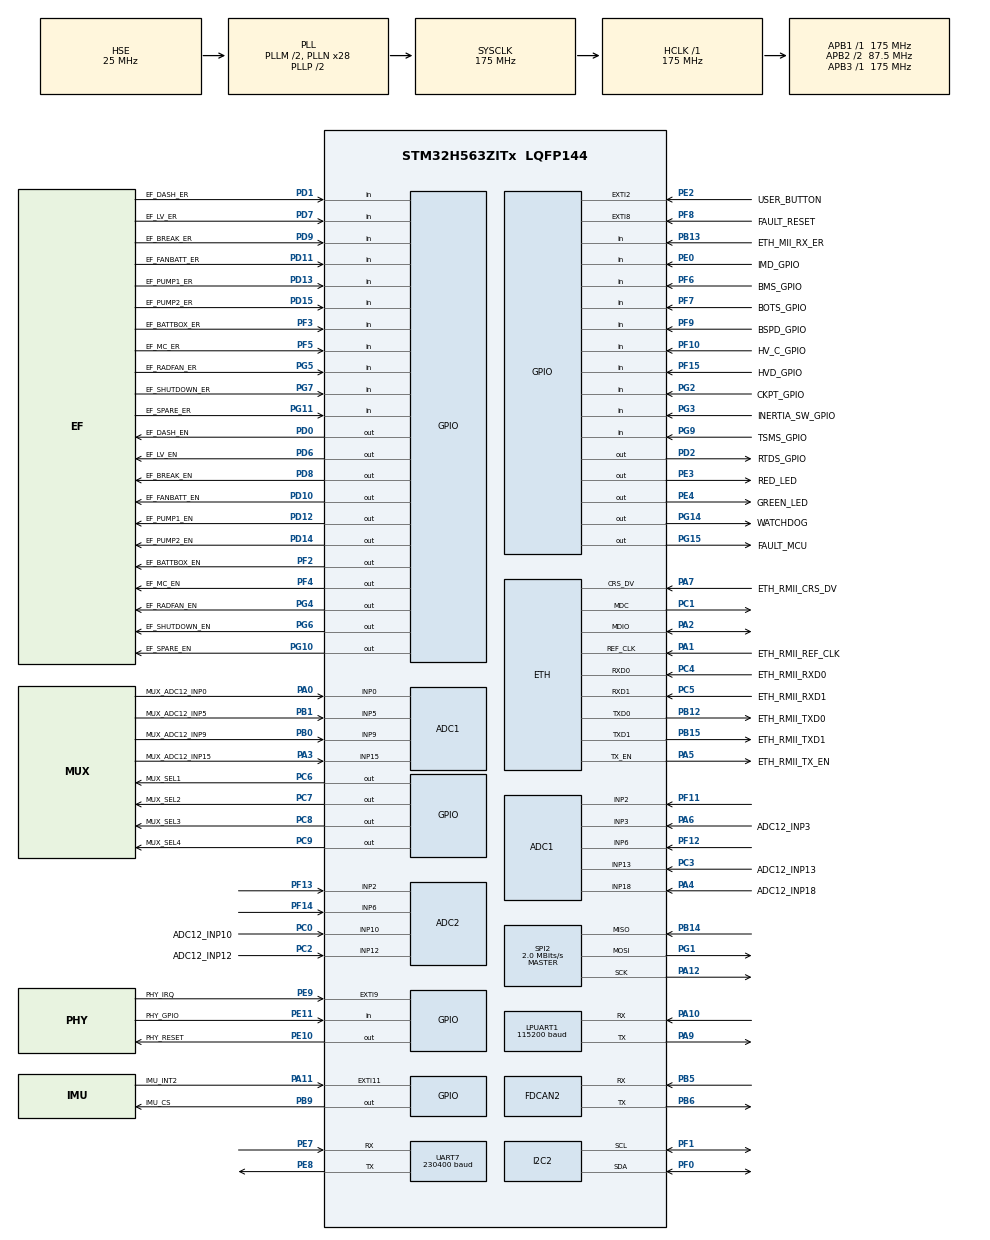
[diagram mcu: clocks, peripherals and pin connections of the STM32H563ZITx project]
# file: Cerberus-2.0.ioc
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ADC1.Channel-11\#ChannelRegularConversion=ADC_CHANNEL_3
ADC1.Channel-22\#ChannelRegularConversion=ADC_CHANNEL_0
ADC1.Channel-23\#ChannelRegularConversion=ADC_CHANNEL_5
ADC1.Channel-24\#ChannelRegularConversion=ADC_CHANNEL_9
ADC1.Channel-25\#ChannelRegularConversion=ADC_CHANNEL_6
ADC1.Channel-26\#ChannelRegularConversion=ADC_CHANNEL_2
ADC1.Channel-27\#ChannelRegularConversion=ADC_CHANNEL_13
ADC1.Channel-28\#ChannelRegularConversion=ADC_CHANNEL_18
ADC1.Channel-29\#ChannelRegularConversion=ADC_CHANNEL_15
ADC1.ClockPrescaler=ADC_CLOCK_ASYNC_DIV64
ADC1.ContinuousConvMode=ENABLE
ADC1.ConversionDataManagement=ADC_CONVERSIONDATA_DMA_CIRCULAR
ADC1.DMAContinuousRequests=ENABLE
ADC1.EOCSelection=ADC_EOC_SEQ_CONV
ADC1.MonitoredBy-11\#ChannelRegularConversion=__NULL
ADC1.MonitoredBy-22\#ChannelRegularConversion=__NULL
ADC1.MonitoredBy-23\#ChannelRegularConversion=__NULL
ADC1.MonitoredBy-24\#ChannelRegularConversion=__NULL
ADC1.MonitoredBy-25\#ChannelRegularConversion=__NULL
ADC1.MonitoredBy-26\#ChannelRegularConversion=__NULL
ADC1.MonitoredBy-27\#ChannelRegularConversion=__NULL
ADC1.MonitoredBy-28\#ChannelRegularConversion=__NULL
ADC1.MonitoredBy-29\#ChannelRegularConversion=__NULL
ADC1.NbrOfConversion=9
ADC1.NbrOfConversionFlag=1
ADC1.OffsetNumber-11\#ChannelRegularConversion=ADC_OFFSET_NONE
ADC1.OffsetNumber-22\#ChannelRegularConversion=ADC_OFFSET_NONE
ADC1.OffsetNumber-23\#ChannelRegularConversion=ADC_OFFSET_NONE
ADC1.OffsetNumber-24\#ChannelRegularConversion=ADC_OFFSET_NONE
ADC1.OffsetNumber-25\#ChannelRegularConversion=ADC_OFFSET_NONE
ADC1.OffsetNumber-26\#ChannelRegularConversion=ADC_OFFSET_NONE
ADC1.OffsetNumber-27\#ChannelRegularConversion=ADC_OFFSET_NONE
ADC1.OffsetNumber-28\#ChannelRegularConversion=ADC_OFFSET_NONE
ADC1.OffsetNumber-29\#ChannelRegularConversion=ADC_OFFSET_NONE
ADC1.Overrun=ADC_OVR_DATA_OVERWRITTEN
ADC1.Rank-11\#ChannelRegularConversion=1
ADC1.Rank-22\#ChannelRegularConversion=2
ADC1.Rank-23\#ChannelRegularConversion=3
ADC1.Rank-24\#ChannelRegularConversion=4
ADC1.Rank-25\#ChannelRegularConversion=5
ADC1.Rank-26\#ChannelRegularConversion=6
ADC1.Rank-27\#ChannelRegularConversion=7
ADC1.Rank-28\#ChannelRegularConversion=8
ADC1.Rank-29\#ChannelRegularConversion=9
ADC1.SamplingTime-11\#ChannelRegularConversion=ADC_SAMPLETIME_47CYCLES_5
ADC1.SamplingTime-22\#ChannelRegularConversion=ADC_SAMPLETIME_47CYCLES_5
ADC1.SamplingTime-23\#ChannelRegularConversion=ADC_SAMPLETIME_47CYCLES_5
ADC1.SamplingTime-24\#ChannelRegularConversion=ADC_SAMPLETIME_47CYCLES_5
ADC1.SamplingTime-25\#ChannelRegularConversion=ADC_SAMPLETIME_47CYCLES_5
ADC1.SamplingTime-26\#ChannelRegularConversion=ADC_SAMPLETIME_47CYCLES_5
ADC1.SamplingTime-27\#ChannelRegularConversion=ADC_SAMPLETIME_47CYCLES_5
ADC1.SamplingTime-28\#ChannelRegularConversion=ADC_SAMPLETIME_47CYCLES_5
ADC1.SamplingTime-29\#ChannelRegularConversion=ADC_SAMPLETIME_247CYCLES_5
ADC1.master=1
ADC2.Channel-2\#ChannelRegularConversion=ADC_CHANNEL_12
ADC2.Channel-3\#ChannelRegularConversion=ADC_CHANNEL_10
ADC2.Channel-4\#ChannelRegularConversion=ADC_CHANNEL_2
ADC2.Channel-5\#ChannelRegularConversion=ADC_CHANNEL_6
ADC2.ClockPrescaler=ADC_CLOCK_ASYNC_DIV64
ADC2.ContinuousConvMode=ENABLE
ADC2.ConversionDataManagement=ADC_CONVERSIONDATA_DMA_CIRCULAR
ADC2.DMAContinuousRequests=ENABLE
ADC2.EOCSelection=ADC_EOC_SEQ_CONV
ADC2.MonitoredBy-2\#ChannelRegularConversion=__NULL
ADC2.MonitoredBy-3\#ChannelRegularConversion=__NULL
ADC2.MonitoredBy-4\#ChannelRegularConversion=__NULL
ADC2.MonitoredBy-5\#ChannelRegularConversion=__NULL
ADC2.NbrOfConversion=4
ADC2.NbrOfConversionFlag=1
ADC2.OffsetNumber-2\#ChannelRegularConversion=ADC_OFFSET_NONE
ADC2.OffsetNumber-3\#ChannelRegularConversion=ADC_OFFSET_NONE
ADC2.OffsetNumber-4\#ChannelRegularConversion=ADC_OFFSET_NONE
ADC2.OffsetNumber-5\#ChannelRegularConversion=ADC_OFFSET_NONE
ADC2.Overrun=ADC_OVR_DATA_OVERWRITTEN
ADC2.Rank-2\#ChannelRegularConversion=1
ADC2.Rank-3\#ChannelRegularConversion=2
ADC2.Rank-4\#ChannelRegularConversion=3
ADC2.Rank-5\#ChannelRegularConversion=4
ADC2.SamplingTime-2\#ChannelRegularConversion=ADC_SAMPLETIME_2CYCLES_5
ADC2.SamplingTime-3\#ChannelRegularConversion=ADC_SAMPLETIME_2CYCLES_5
ADC2.SamplingTime-4\#ChannelRegularConversion=ADC_SAMPLETIME_2CYCLES_5
ADC2.SamplingTime-5\#ChannelRegularConversion=ADC_SAMPLETIME_2CYCLES_5
BOOTPATH.BootPathName=LEGACY
BOOTPATH.UserSelectedBootPath=LEGACY
CORTEX_M33_NS.userName=CORTEX_M33
ETH.MediaInterface=HAL_ETH_RMII_MODE
FDCAN2.CalculateBaudRateNominal=500000
FDCAN2.CalculateTimeBitNominal=2000
FDCAN2.CalculateTimeQuantumNominal=125.0
FDCAN2.ExtFiltersNbr=8
FDCAN2.Mode=FDCAN_MODE_NORMAL
FDCAN2.NominalPrescaler=8
FDCAN2.NominalTimeSeg1=11
FDCAN2.NominalTimeSeg2=4
FDCAN2.StdFiltersNbr=12
GPDMA1.CIRCULARMODE_GPDMACH4=ENABLE
GPDMA1.CIRCULARMODE_GPDMACH5=ENABLE
GPDMA1.DESTDATAWIDTH_GPDMACH4=DMA_DEST_DATAWIDTH_HALFWORD
GPDMA1.DESTDATAWIDTH_GPDMACH5=DMA_DEST_DATAWIDTH_HALFWORD
GPDMA1.DESTINC_GPDMACH4=DMA_DINC_INCREMENTED
GPDMA1.DESTINC_GPDMACH5=DMA_DINC_INCREMENTED
GPDMA1.DIRECTION_GPDMACH0=DMA_MEMORY_TO_PERIPH
GPDMA1.IPHANDLE_GPDMACH0-SIMPLEREQUEST_GPDMACH0=__NULL
GPDMA1.IPHANDLE_GPDMACH4-SIMPLEREQUEST_GPDMACH4=__NULL
GPDMA1.IPHANDLE_GPDMACH5-SIMPLEREQUEST_GPDMACH5=__NULL
GPDMA1.PRIORITY_GPDMACH0=DMA_LOW_PRIORITY_MID_WEIGHT
GPDMA1.REQUEST_GPDMACH0=GPDMA1_REQUEST_UART7_TX
GPDMA1.REQUEST_GPDMACH4=GPDMA1_REQUEST_ADC2
GPDMA1.REQUEST_GPDMACH5=GPDMA1_REQUEST_ADC1
GPDMA1.SRCDATAWIDTH_GPDMACH4=DMA_SRC_DATAWIDTH_HALFWORD
GPDMA1.SRCDATAWIDTH_GPDMACH5=DMA_SRC_DATAWIDTH_HALFWORD
GPDMA1.SRCINC_GPDMACH0=DMA_SINC_INCREMENTED
I2C2.Timing=0x60606293
IWDG.Prescaler=IWDG_PRESCALER_32
LPUART1.BaudRate=115200
Mcu.Family=STM32H5
Mcu.Name=STM32H563ZITx
Mcu.Package=LQFP144
NETXDUO.ETH_ON=1
NETXDUO.NX_APP_MEM_POOL_SIZE=10240
NETXDUO.NX_ENABLE_VLAN=false
NETXDUO.NX_MAX_MULTICAST_GROUPS=256
NVIC.ETH_IRQn=true\:0\:0\:false\:false\:true\:false\:true\:true\:true
NVIC.ETH_WKUP_IRQn=true\:0\:0\:false\:false\:true\:false\:true\:true\:true
NVIC.EXTI11_IRQn=true\:0\:0\:false\:false\:true\:false\:true\:true\:true
NVIC.EXTI2_IRQn=true\:0\:0\:false\:false\:true\:false\:true\:true\:true
NVIC.EXTI8_IRQn=true\:0\:0\:false\:false\:true\:false\:true\:true\:true
NVIC.FDCAN2_IT0_IRQn=true\:0\:0\:false\:false\:true\:false\:true\:true\:true
NVIC.FDCAN2_IT1_IRQn=true\:0\:0\:false\:false\:true\:false\:true\:true\:true
NVIC.GPDMA1_Channel0_IRQn=true\:0\:0\:false\:false\:true\:true\:false\:true\:true
NVIC.GPDMA1_Channel4_IRQn=true\:0\:0\:false\:false\:true\:true\:false\:true\:true
NVIC.GPDMA1_Channel5_IRQn=true\:0\:0\:false\:false\:true\:true\:false\:true\:true
NVIC.PriorityGroup=NVIC_PRIORITYGROUP_4
NVIC.TIM1_UP_IRQn=true\:15\:0\:false\:false\:true\:false\:false\:true\:true
NVIC.TimeBase=TIM1_UP_IRQn
NVIC.TimeBaseIP=TIM1
NVIC.UART7_IRQn=true\:0\:0\:false\:false\:true\:false\:true\:true\:true
PA0.GPIO_Label=MUX_ADC12_INP0
PA0.Signal=ADCx_INP0
PA1.GPIO_Label=ETH_RMII_REF_CLK
PA1.Mode=RMII
PA1.Signal=ETH_REF_CLK
PA10.Mode=Asynchronous
PA10.Signal=LPUART1_RX
PA11.GPIO_Label=IMU_INT2
PA11.Signal=GPXTI11
PA12.Mode=Full_Duplex_Master
PA12.Signal=SPI2_SCK
PA13(JTMS/SWDIO).GPIO_Label=JTMS
PA13(JTMS/SWDIO).Signal=DEBUG_JTMS-SWDIO
PA14(JTCK/SWCLK).GPIO_Label=JTCK
PA14(JTCK/SWCLK).Signal=DEBUG_JTCK-SWCLK
PA15(JTDI).GPIO_Label=JTDI
PA15(JTDI).Signal=DEBUG_JTDI
PA2.Mode=RMII
PA2.Signal=ETH_MDIO
PA3.GPIO_Label=MUX_ADC12_INP15
PA3.Signal=ADCx_INP15
PA4.GPIO_Label=ADC12_INP18
PA4.Signal=ADCx_INP18
PA5.GPIO_Label=ETH_RMII_TX_EN
PA5.Mode=RMII
PA5.Signal=ETH_TX_EN
PA6.GPIO_Label=ADC12_INP3
PA6.Signal=ADCx_INP3
PA7.GPIO_Label=ETH_RMII_CRS_DV
PA7.Mode=RMII
PA7.Signal=ETH_CRS_DV
PA9.Mode=Asynchronous
PA9.Signal=LPUART1_TX
PB0.GPIO_Label=MUX_ADC12_INP9
PB0.Signal=ADCx_INP9
PB1.GPIO_Label=MUX_ADC12_INP5
PB1.Signal=ADCx_INP5
PB12.GPIO_Label=ETH_RMII_TXD0
PB12.Mode=RMII
PB12.Signal=ETH_TXD0
PB13.GPIO_Label=ETH_MII_RX_ER
PB13.Signal=GPIO_Input
PB14.Mode=Full_Duplex_Master
PB14.Signal=SPI2_MISO
PB15.GPIO_Label=ETH_RMII_TXD1
PB15.Mode=RMII
PB15.Signal=ETH_TXD1
PB3(JTDO/TRACESWO).GPIO_Label=JTDO
PB3(JTDO/TRACESWO).Signal=DEBUG_JTDO-SWO
PB5.Mode=FDCAN_Activate
PB5.Signal=FDCAN2_RX
PB6.Mode=FDCAN_Activate
PB6.Signal=FDCAN2_TX
PB9.GPIO_Label=IMU_CS
PB9.PinState=GPIO_PIN_SET
PB9.Signal=GPIO_Output
PC0.GPIO_Label=ADC12_INP10
PC0.Signal=ADCx_INP10
PC1.Mode=RMII
PC1.Signal=ETH_MDC
PC14-OSC32_IN(OSC32_IN).Mode=LSE-External-Oscillator
PC14-OSC32_IN(OSC32_IN).Signal=RCC_OSC32_IN
PC15-OSC32_OUT(OSC32_OUT).Mode=LSE-External-Oscillator
PC15-OSC32_OUT(OSC32_OUT).Signal=RCC_OSC32_OUT
PC2.GPIO_Label=ADC12_INP12
PC2.Signal=ADCx_INP12
PC3.GPIO_Label=ADC12_INP13
PC3.Signal=ADCx_INP13
PC4.GPIO_Label=ETH_RMII_RXD0
PC4.Mode=RMII
PC4.Signal=ETH_RXD0
PC5.GPIO_Label=ETH_RMII_RXD1
PC5.Mode=RMII
PC5.Signal=ETH_RXD1
PC6.GPIO_Label=MUX_SEL1
PC6.Signal=GPIO_Output
PC7.GPIO_Label=MUX_SEL2
PC7.Signal=GPIO_Output
PC8.GPIO_Label=MUX_SEL3
PC8.Signal=GPIO_Output
PC9.GPIO_Label=MUX_SEL4
PC9.Signal=GPIO_Output
PD0.GPIO_Label=EF_DASH_EN
PD0.Signal=GPIO_Output
PD1.GPIO_Label=EF_DASH_ER
PD1.GPIO_PuPd=GPIO_PULLUP
PD1.Signal=GPIO_Input
PD10.GPIO_Label=EF_FANBATT_EN
PD10.Signal=GPIO_Output
PD11.GPIO_Label=EF_FANBATT_ER
PD11.GPIO_PuPd=GPIO_PULLUP
PD11.Signal=GPIO_Input
PD12.GPIO_Label=EF_PUMP1_EN
PD12.Signal=GPIO_Output
PD13.GPIO_Label=EF_PUMP1_ER
PD13.GPIO_PuPd=GPIO_PULLUP
PD13.Signal=GPIO_Input
PD14.GPIO_Label=EF_PUMP2_EN
PD14.Signal=GPIO_Output
PD15.GPIO_Label=EF_PUMP2_ER
PD15.GPIO_PuPd=GPIO_PULLUP
PD15.Signal=GPIO_Input
PD2.GPIO_Label=RTDS_GPIO
PD2.Signal=GPIO_Output
PD6.GPIO_Label=EF_LV_EN
PD6.GPIO_PuPd=GPIO_PULLUP
PD6.PinState=GPIO_PIN_SET
PD6.Signal=GPIO_Output
PD7.GPIO_Label=EF_LV_ER
PD7.GPIO_PuPd=GPIO_PULLUP
PD7.Signal=GPIO_Input
PD8.GPIO_Label=EF_BREAK_EN
PD8.Signal=GPIO_Output
PD9.GPIO_Label=EF_BREAK_ER
PD9.GPIO_PuPd=GPIO_PULLUP
PD9.Signal=GPIO_Input
PE0.GPIO_Label=IMD_GPIO
PE0.Signal=GPIO_Input
PE10.GPIO_Label=PHY_RESET
PE10.Signal=GPIO_Output
PE11.GPIO_Label=PHY_GPIO
PE11.Signal=GPIO_Input
PE2.GPIO_Label=USER_BUTTON
PE2.GPIO_ModeDefaultEXTI=GPIO_MODE_IT_FALLING
PE2.GPIO_PuPd=GPIO_PULLUP
PE2.Signal=GPXTI2
PE3.GPIO_Label=RED_LED
PE3.Signal=GPIO_Output
PE4.GPIO_Label=GREEN_LED
PE4.Signal=GPIO_Output
PE7.Mode=Asynchronous
PE7.Signal=UART7_RX
PE8.Mode=Asynchronous
PE8.Signal=UART7_TX
PE9.GPIO_Label=PHY_IRQ
PE9.GPIO_ModeDefaultEXTI=GPIO_MODE_IT_FALLING
PE9.Signal=GPXTI9
PF0.Mode=I2C
PF0.Signal=I2C2_SDA
PF1.Mode=I2C
PF1.Signal=I2C2_SCL
PF10.GPIO_Label=HV_C_GPIO
PF10.Signal=GPIO_Input
PF11.Mode=IN2-Single-Ended
PF11.Signal=ADC1_INP2
PF12.Mode=IN6-Single-Ended
PF12.Signal=ADC1_INP6
PF13.Mode=IN2-Single-Ended
PF13.Signal=ADC2_INP2
PF14.Mode=IN6-Single-Ended
PF14.Signal=ADC2_INP6
PF15.GPIO_Label=HVD_GPIO
PF15.Signal=GPIO_Input
PF2.GPIO_Label=EF_BATTBOX_EN
PF2.GPIO_PuPd=GPIO_PULLUP
PF2.PinState=GPIO_PIN_SET
PF2.Signal=GPIO_Output
PF3.GPIO_Label=EF_BATTBOX_ER
PF3.GPIO_PuPd=GPIO_PULLUP
PF3.Signal=GPIO_Input
PF4.GPIO_Label=EF_MC_EN
PF4.Signal=GPIO_Output
PF5.GPIO_Label=EF_MC_ER
PF5.GPIO_PuPd=GPIO_PULLUP
PF5.Signal=GPIO_Input
PF6.GPIO_Label=BMS_GPIO
PF6.Signal=GPIO_Input
PF7.GPIO_Label=BOTS_GPIO
PF7.Signal=GPIO_Input
PF8.GPIO_Label=FAULT_RESET
PF8.GPIO_ModeDefaultEXTI=GPIO_MODE_IT_FALLING
PF8.Signal=GPXTI8
PF9.GPIO_Label=BSPD_GPIO
PF9.Signal=GPIO_Input
PG1.Mode=Full_Duplex_Master
PG1.Signal=SPI2_MOSI
PG10.GPIO_Label=EF_SPARE_EN
PG10.Signal=GPIO_Output
PG11.GPIO_Label=EF_SPARE_ER
PG11.GPIO_PuPd=GPIO_PULLUP
PG11.Signal=GPIO_Input
PG14.GPIO_Label=WATCHDOG
PG14.Signal=GPIO_Output
PG15.GPIO_Label=FAULT_MCU
PG15.PinState=GPIO_PIN_SET
PG15.Signal=GPIO_Output
PG2.GPIO_Label=CKPT_GPIO
PG2.Signal=GPIO_Input
PG3.GPIO_Label=INERTIA_SW_GPIO
PG3.Signal=GPIO_Input
PG4.GPIO_Label=EF_RADFAN_EN
PG4.Signal=GPIO_Output
PG5.GPIO_Label=EF_RADFAN_ER
PG5.GPIO_PuPd=GPIO_PULLUP
PG5.Signal=GPIO_Input
PG6.GPIO_Label=EF_SHUTDOWN_EN
PG6.GPIO_PuPd=GPIO_PULLUP
PG6.PinState=GPIO_PIN_SET
PG6.Signal=GPIO_Output
PG7.GPIO_Label=EF_SHUTDOWN_ER
PG7.GPIO_PuPd=GPIO_PULLUP
PG7.Signal=GPIO_Input
PG9.GPIO_Label=TSMS_GPIO
PG9.Signal=GPIO_Input
PH0-OSC_IN(PH0).Mode=HSE-External-Oscillator
PH0-OSC_IN(PH0).Signal=RCC_OSC_IN
PH1-OSC_OUT(PH1).Mode=HSE-External-Oscillator
PH1-OSC_OUT(PH1).Signal=RCC_OSC_OUT
ProjectManager.HeapSize=0x200
ProjectManager.StackSize=0x400
ProjectManager.TargetToolchain=CMake
RCC.ADCFreq_Value=175000000
RCC.AHBFreq_Value=175000000
RCC.APB1Freq_Value=175000000
RCC.APB1TimFreq_Value=175000000
RCC.APB2CLKDivider=RCC_HCLK_DIV2
RCC.APB2Freq_Value=87500000
RCC.APB2TimFreq_Value=175000000
RCC.APB3Freq_Value=175000000
RCC.CSI_VALUE=4000000
RCC.CortexFreq_Value=175000000
RCC.EPOD_VALUE=25000000
RCC.FDCANClockSelection=RCC_FDCANCLKSOURCE_PLL2Q
RCC.HCLKFreq_Value=175000000
RCC.HSE_VALUE=25000000
RCC.HSI48_VALUE=48000000
RCC.HSI_VALUE=64000000
RCC.LSIRC_VALUE=32000
RCC.PLL1Q=7
RCC.PLL2FRACN=0
RCC.PLL2M=5
RCC.PLL2N=64
RCC.PLL2P=5
RCC.PLL2Q=5
RCC.PLL2Source=RCC_PLL2_SOURCE_HSE
RCC.PLLFRACN=0
RCC.PLLM=2
RCC.PLLN=28
RCC.PLLSourceVirtual=RCC_PLL1_SOURCE_HSE
RCC.SPI2CLockSelection=RCC_SPI2CLKSOURCE_PLL2P
RCC.SYSCLKFreq_VALUE=175000000
RCC.SYSCLKSource=RCC_SYSCLKSOURCE_PLLCLK
RCC.USBFreq_Value=48000000
RCC.VCOOutputFreq_Value=350000000
SH.ADCx_INP0.0=ADC1_INP0,IN0-Single-Ended
SH.ADCx_INP0.1=ADC2_INP0,IN0-Single-Ended
SH.ADCx_INP10.0=ADC1_INP10
SH.ADCx_INP10.1=ADC2_INP10,IN10-Single-Ended
SH.ADCx_INP12.0=ADC1_INP12
SH.ADCx_INP12.1=ADC2_INP12,IN12-Single-Ended
SH.ADCx_INP13.0=ADC1_INP13,IN13-Single-Ended
SH.ADCx_INP13.1=ADC2_INP13,IN13-Single-Ended
SH.ADCx_INP15.0=ADC1_INP15,IN15-Single-Ended
SH.ADCx_INP15.1=ADC2_INP15,IN15-Single-Ended
SH.ADCx_INP18.0=ADC2_INP18
SH.ADCx_INP18.1=ADC1_INP18,IN18-Single-Ended
SH.ADCx_INP3.0=ADC2_INP3
SH.ADCx_INP3.1=ADC1_INP3,IN3-Single-Ended
SH.ADCx_INP5.0=ADC2_INP5
SH.ADCx_INP5.1=ADC1_INP5,IN5-Single-Ended
SH.ADCx_INP9.0=ADC1_INP9,IN9-Single-Ended
SH.ADCx_INP9.1=ADC2_INP9,IN9-Single-Ended
SPI2.BaudRatePrescaler=SPI_BAUDRATEPRESCALER_32
SPI2.CalculateBaudRate=2.0 MBits/s
SPI2.DataSize=SPI_DATASIZE_8BIT
SPI2.Direction=SPI_DIRECTION_2LINES
SPI2.Mode=SPI_MODE_MASTER
SPI2.VirtualType=VM_MASTER
THREADX.TX_APP_GENERATE_INIT_CODE=false
THREADX.TX_APP_MEM_POOL_SIZE=46080
THREADX.TX_ENABLE_EVENT_TRACE=1
THREADX.TX_TIMER_TICKS_PER_SECOND=1000
UART7.BaudRate=230400
UART7.Mode=MODE_TX
VP_BOOTPATH_VS_BOOTPATH.Mode=BP_Activate
VP_CORTEX_M33_NS_VS_Hclk.Mode=Hclk_Mode
VP_DCACHE1_VS_DCACHE.Mode=DCACHE_Activate
VP_GPDMA1_VS_GPDMACH0.Mode=SIMPLEREQUEST_GPDMACH0
VP_GPDMA1_VS_GPDMACH4.Mode=SIMPLEREQUEST_GPDMACH4
VP_GPDMA1_VS_GPDMACH5.Mode=SIMPLEREQUEST_GPDMACH5
VP_ICACHE_VS_ICACHE.Mode=DirectMappedCache
VP_IWDG_VS_IWDG.Mode=IWDG_Activate
VP_MEMORYMAP_VS_MEMORYMAP.Mode=CurAppReg
VP_NETXDUO_VS_AddonsOoMQTT.Mode=Addons_MQTT
VP_NETXDUO_VS_EthernetOoPhyOoInterface.Mode=Custom_Phy_Interface
VP_NETXDUO_VS_NXOoCore.Mode=NX_Core
VP_NETXDUO_VS_NetworkOoInterface.Mode=Ethernet_Interface
VP_PWR_VS_LPOM.Mode=PowerOptimisation
VP_PWR_VS_SECSignals.Mode=Security/Privilege
VP_SYS_VS_tim1.Mode=TIM1
VP_THREADX_VS_RTOSJjThreadXJjCoreJjDefault.Mode=Core_Default
VP_THREADX_VS_RTOSJjThreadXJjTraceX_SupportJjDefault.Mode=TraceX_Support_Default
board=custom

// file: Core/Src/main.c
/* USER CODE BEGIN Header */
/**
  ******************************************************************************
  * @file           : main.c
  * @brief          : Main program body
  ******************************************************************************
  * @attention
  *
  * Copyright (c) 2025 STMicroelectronics.
  * All rights reserved.
  *
  * This software is licensed under terms that can be found in the LICENSE file
  * in the root directory of this software component.
  * If no LICENSE file comes with this software, it is provided AS-IS.
  *
  ******************************************************************************
  */
/* USER CODE END Header */
#include "app_threadx.h"
#include "main.h"

/* USER CODE BEGIN Includes */
#include <stdio.h>
#include <string.h>
#include <stdint.h>

#include "fdcan.h"
#include "u_can.h"
#include "u_faults.h"
#include "u_queues.h"
#include "u_debug.h"
#include "u_lightning.h"
#include "u_tx_debug.h"
#include "traceout.h"
#include "can_messages_tx.h"
/* USER CODE END Includes */

ETH_DMADescTypeDef  DMARxDscrTab[ETH_RX_DESC_CNT]; /* Ethernet Rx DMA Descriptors */
ETH_DMADescTypeDef  DMATxDscrTab[ETH_TX_DESC_CNT]; /* Ethernet Tx DMA Descriptors */

ADC_HandleTypeDef hadc1;
ADC_HandleTypeDef hadc2;
DMA_NodeTypeDef Node_GPDMA1_Channel5;
DMA_QListTypeDef List_GPDMA1_Channel5;
DMA_HandleTypeDef handle_GPDMA1_Channel5;
DMA_NodeTypeDef Node_GPDMA1_Channel4;
DMA_QListTypeDef List_GPDMA1_Channel4;
DMA_HandleTypeDef handle_GPDMA1_Channel4;

DCACHE_HandleTypeDef hdcache1;

ETH_HandleTypeDef heth;

FDCAN_HandleTypeDef hfdcan2;

I2C_HandleTypeDef hi2c2;

IWDG_HandleTypeDef hiwdg;

UART_HandleTypeDef hlpuart1;
UART_HandleTypeDef huart7;
DMA_HandleTypeDef handle_GPDMA1_Channel0;

SPI_HandleTypeDef hspi2;

void SystemClock_Config(void);
void PeriphCommonClock_Config(void);
static void MX_GPDMA1_Init(void);
static void MX_GPIO_Init(void);
static void MX_ICACHE_Init(void);
static void MX_ADC1_Init(void);
static void MX_ADC2_Init(void);
static void MX_FDCAN2_Init(void);
static void MX_ETH_Init(void);
static void MX_I2C2_Init(void);
static void MX_LPUART1_UART_Init(void);
static void MX_SPI2_Init(void);
static void MX_UART7_Init(void);
static void MX_DCACHE1_Init(void);
static void MX_IWDG_Init(void);

/* USER CODE BEGIN 0 */

/* Make printf() use LPUART1 */
int _write(int file, char *ptr, int len)
{
    HAL_UART_Transmit(&hlpuart1, (uint8_t*)ptr, len, HAL_MAX_DELAY);
    return len;
}

/* FDCAN FIFO0 Interrupt Callback */
/* Callback for any FIFO0 interrupt stuff */
void HAL_FDCAN_RxFifo0Callback(FDCAN_HandleTypeDef *hfdcan, uint32_t RxFifo0ITs)
{
  //PRINTLN_INFO("HAL_FDCAN callback triggered");

	/* If a message has just been recieved... */
	if (RxFifo0ITs & FDCAN_IT_RX_FIFO0_NEW_MESSAGE)
	{
		can_msg_t message;
		FDCAN_RxHeaderTypeDef rx_header;

    /* Get the message. */
    HAL_StatusTypeDef status = HAL_FDCAN_GetRxMessage(hfdcan, FDCAN_RX_FIFO0, &rx_header, message.data);
    if(status != HAL_OK) {
      PRINTLN_ERROR("Failed to call HAL_FDCAN_GetRxMessage() (Status: %d/%s).", status, hal_status_toString(status));
      queue_send(&faults, &(fault_t){CAN_INCOMING_FAULT}, TX_NO_WAIT);
      return;
    }

    /* Pack the message into the struct. */
    message.id = rx_header.Identifier;
		message.id_is_extended = (rx_header.IdType == FDCAN_EXTENDED_ID);
	  message.len = (uint8_t)rx_header.DataLength;

		/* Check message size */
		if (rx_header.DataLength > 8)
		{
			PRINTLN_ERROR("Recieved CAN message is larger than 8 bytes (rx_header.DataLength: %ld, id: 0x%lX).", rx_header.DataLength, rx_header.Identifier);
      queue_send(&faults, &(fault_t){CAN_INCOMING_FAULT}, TX_NO_WAIT);
			return;
		}

		/* Send message to incoming CAN queue */
    queue_send(&can_incoming, &message, TX_NO_WAIT);
	}
}

/* BusOff Error Handling. */
void HAL_FDCAN_ErrorStatusCallback(FDCAN_HandleTypeDef *hfdcan, uint32_t ErrorStatusITs)
{
    FDCAN_ProtocolStatusTypeDef protocol_status;
    HAL_FDCAN_GetProtocolStatus(hfdcan, &protocol_status);

    if (protocol_status.BusOff != 0)  // If Bus-Off error occurred
    {
        PRINTLN_ERROR("CAN ENCOUNTERED BUS OFF STATE");
        CLEAR_BIT(hfdcan->Instance->CCCR, FDCAN_CCCR_INIT);  // Clear INIT bit to recover from Bus-Off
        /* get the FDCAN hal errors. */
        uint8_t status = HAL_FDCAN_GetError(can1.hcan);
        printf("can - HAL_FDCAN_GetError() status: %d\n", status);

        FDCAN_ProtocolStatusTypeDef statt = { 0 };
        status = HAL_FDCAN_GetProtocolStatus(can1.hcan, &statt);
        printf("can - HAL_FDCAN_GetProtocolStatus() status: %d\n", status);

        /* Big statt */
        printf("can - HAL_FDCAN_GetProtocolStatus() - LastErrorCode=%ld\n", statt.LastErrorCode);
        printf("can - HAL_FDCAN_GetProtocolStatus() - DataLastErrorCode=%ld\n", statt.DataLastErrorCode);
        printf("can - HAL_FDCAN_GetProtocolStatus() - Activity=%ld\n", statt.Activity);
        printf("can - HAL_FDCAN_GetProtocolStatus() - ErrorPassive=%ld\n", statt.ErrorPassive);
        printf("can - HAL_FDCAN_GetProtocolStatus() - Warning=%ld\n", statt.Warning);
        printf("can - HAL_FDCAN_GetProtocolStatus() - BusOff=%ld\n", statt.BusOff);
        printf("can - HAL_FDCAN_GetProtocolStatus() - RxESIflag=%ld\n", statt.RxESIflag);
        printf("can - HAL_FDCAN_GetProtocolStatus() - RxBRSflag=%ld\n", statt.RxBRSflag);
        printf("can - HAL_FDCAN_GetProtocolStatus() - RxFDFflag=%ld\n", statt.RxFDFflag);
        printf("can - HAL_FDCAN_GetProtocolStatus() - ProtocolException=%ld\n", statt.ProtocolException);
        printf("can - HAL_FDCAN_GetProtocolStatus() - TDCvalue=%ld\n", statt.TDCvalue);

        FDCAN_ErrorCountersTypeDef statt2 = { 0 };
        status = HAL_FDCAN_GetErrorCounters(can1.hcan, &statt2);
        printf("can - HAL_FDCAN_GetErrorCounters() status: %d\n", status);
        printf("can - HAL_FDCAN_GetErrorCounters() - TxErrorCnt: %ld\n", statt2.TxErrorCnt);
        printf("can - HAL_FDCAN_GetErrorCounters() - RxErrorCnt: %ld\n", statt2.RxErrorCnt);
        printf("can - HAL_FDCAN_GetErrorCounters() - RxErrorPassive: %ld\n", statt2.RxErrorPassive);
        printf("can - HAL_FDCAN_GetErrorCounters() - ErrorLogging: %ld\n", statt2.ErrorLogging);
    }
}

void HAL_GPIO_EXTI_Falling_Callback(uint16_t GPIO_Pin)
{
	if (GPIO_Pin == USER_BUTTON_Pin) {
		traceout_start_from_isr();
	}

  if (GPIO_Pin == FAULT_RESET_Pin) {
    send_reset_latching_fault(true);
  }
}

/* USER CODE END 0 */

int main(void)
{

  /* MCU Configuration--------------------------------------------------------*/

  /* Reset of all peripherals, Initializes the Flash interface and the Systick. */
  HAL_Init();

  /* Configure the system clock */
  SystemClock_Config();

  /* Configure the peripherals common clocks */
  PeriphCommonClock_Config();

  /* USER CODE BEGIN SysInit */
  //HAL_Delay(10000);
  /* USER CODE END SysInit */

  /* Initialize all configured peripherals */
  MX_GPDMA1_Init();
  MX_GPIO_Init();
  MX_ICACHE_Init();
  MX_ADC1_Init();
  MX_ADC2_Init();
  MX_FDCAN2_Init();
  MX_ETH_Init();
  MX_I2C2_Init();
  MX_LPUART1_UART_Init();
  MX_SPI2_Init();
  MX_UART7_Init();
  MX_DCACHE1_Init();
  MX_IWDG_Init();
  /* USER CODE BEGIN 2 */

  /* Init CAN */
  can1_init(&hfdcan2);
  printf("thing\n");

  /* USER CODE END 2 */

  MX_ThreadX_Init();

  /* We should never get here as control is now taken by the scheduler */

  /* Infinite loop */
  while (1)
  {

  }
}

void SystemClock_Config(void)
{
  RCC_OscInitTypeDef RCC_OscInitStruct = {0};
  RCC_ClkInitTypeDef RCC_ClkInitStruct = {0};

  /** Configure the main internal regulator output voltage
  */
  __HAL_PWR_VOLTAGESCALING_CONFIG(PWR_REGULATOR_VOLTAGE_SCALE1);

  while(!__HAL_PWR_GET_FLAG(PWR_FLAG_VOSRDY)) {}

  /** Initializes the RCC Oscillators according to the specified parameters
  * in the RCC_OscInitTypeDef structure.
  */
  RCC_OscInitStruct.OscillatorType = RCC_OSCILLATORTYPE_LSI|RCC_OSCILLATORTYPE_HSE;
  RCC_OscInitStruct.HSEState = RCC_HSE_ON;
  RCC_OscInitStruct.LSIState = RCC_LSI_ON;
  RCC_OscInitStruct.PLL.PLLState = RCC_PLL_ON;
  RCC_OscInitStruct.PLL.PLLSource = RCC_PLL1_SOURCE_HSE;
  RCC_OscInitStruct.PLL.PLLM = 2;
  RCC_OscInitStruct.PLL.PLLN = 28;
  RCC_OscInitStruct.PLL.PLLP = 2;
  RCC_OscInitStruct.PLL.PLLQ = 7;
  RCC_OscInitStruct.PLL.PLLR = 2;
  RCC_OscInitStruct.PLL.PLLRGE = RCC_PLL1_VCIRANGE_3;
  RCC_OscInitStruct.PLL.PLLVCOSEL = RCC_PLL1_VCORANGE_WIDE;
  RCC_OscInitStruct.PLL.PLLFRACN = 0;
  if (HAL_RCC_OscConfig(&RCC_OscInitStruct) != HAL_OK)
  {
    Error_Handler();
  }

  /** Initializes the CPU, AHB and APB buses clocks
  */
  RCC_ClkInitStruct.ClockType = RCC_CLOCKTYPE_HCLK|RCC_CLOCKTYPE_SYSCLK
                              |RCC_CLOCKTYPE_PCLK1|RCC_CLOCKTYPE_PCLK2
                              |RCC_CLOCKTYPE_PCLK3;
  RCC_ClkInitStruct.SYSCLKSource = RCC_SYSCLKSOURCE_PLLCLK;
  RCC_ClkInitStruct.AHBCLKDivider = RCC_SYSCLK_DIV1;
  RCC_ClkInitStruct.APB1CLKDivider = RCC_HCLK_DIV1;
  RCC_ClkInitStruct.APB2CLKDivider = RCC_HCLK_DIV2;
  RCC_ClkInitStruct.APB3CLKDivider = RCC_HCLK_DIV1;

  if (HAL_RCC_ClockConfig(&RCC_ClkInitStruct, FLASH_LATENCY_5) != HAL_OK)
  {
    Error_Handler();
  }

  /** Configure the programming delay
  */
  __HAL_FLASH_SET_PROGRAM_DELAY(FLASH_PROGRAMMING_DELAY_2);
}

void PeriphCommonClock_Config(void)
{
  RCC_PeriphCLKInitTypeDef PeriphClkInitStruct = {0};

  /** Initializes the peripherals clock
  */
  PeriphClkInitStruct.PeriphClockSelection = RCC_PERIPHCLK_ADCDAC|RCC_PERIPHCLK_FDCAN
                              |RCC_PERIPHCLK_SPI2;
  PeriphClkInitStruct.PLL2.PLL2Source = RCC_PLL2_SOURCE_HSE;
  PeriphClkInitStruct.PLL2.PLL2M = 5;
  PeriphClkInitStruct.PLL2.PLL2N = 64;
  PeriphClkInitStruct.PLL2.PLL2P = 5;
  PeriphClkInitStruct.PLL2.PLL2Q = 5;
  PeriphClkInitStruct.PLL2.PLL2R = 2;
  PeriphClkInitStruct.PLL2.PLL2RGE = RCC_PLL2_VCIRANGE_2;
  PeriphClkInitStruct.PLL2.PLL2VCOSEL = RCC_PLL2_VCORANGE_WIDE;
  PeriphClkInitStruct.PLL2.PLL2FRACN = 0;
  PeriphClkInitStruct.PLL2.PLL2ClockOut = RCC_PLL2_DIVP|RCC_PLL2_DIVQ;
  PeriphClkInitStruct.FdcanClockSelection = RCC_FDCANCLKSOURCE_PLL2Q;
  PeriphClkInitStruct.Spi2ClockSelection = RCC_SPI2CLKSOURCE_PLL2P;
  if (HAL_RCCEx_PeriphCLKConfig(&PeriphClkInitStruct) != HAL_OK)
  {
    Error_Handler();
  }
}

static void MX_ADC1_Init(void)
{

  ADC_ChannelConfTypeDef sConfig = {0};

  /** Common config
  */
  hadc1.Instance = ADC1;
  hadc1.Init.ClockPrescaler = ADC_CLOCK_ASYNC_DIV64;
  hadc1.Init.Resolution = ADC_RESOLUTION_12B;
  hadc1.Init.DataAlign = ADC_DATAALIGN_RIGHT;
  hadc1.Init.ScanConvMode = ADC_SCAN_ENABLE;
  hadc1.Init.EOCSelection = ADC_EOC_SEQ_CONV;
  hadc1.Init.LowPowerAutoWait = DISABLE;
  hadc1.Init.ContinuousConvMode = ENABLE;
  hadc1.Init.NbrOfConversion = 9;
  hadc1.Init.DiscontinuousConvMode = DISABLE;
  hadc1.Init.ExternalTrigConv = ADC_SOFTWARE_START;
  hadc1.Init.ExternalTrigConvEdge = ADC_EXTERNALTRIGCONVEDGE_NONE;
  hadc1.Init.DMAContinuousRequests = ENABLE;
  hadc1.Init.SamplingMode = ADC_SAMPLING_MODE_NORMAL;
  hadc1.Init.Overrun = ADC_OVR_DATA_OVERWRITTEN;
  hadc1.Init.OversamplingMode = DISABLE;
  if (HAL_ADC_Init(&hadc1) != HAL_OK)
  {
    Error_Handler();
  }

  /** Configure Regular Channel
  */
  sConfig.Channel = ADC_CHANNEL_3;
  sConfig.Rank = ADC_REGULAR_RANK_1;
  sConfig.SamplingTime = ADC_SAMPLETIME_47CYCLES_5;
  sConfig.SingleDiff = ADC_SINGLE_ENDED;
  sConfig.OffsetNumber = ADC_OFFSET_NONE;
  sConfig.Offset = 0;
  if (HAL_ADC_ConfigChannel(&hadc1, &sConfig) != HAL_OK)
  {
    Error_Handler();
  }

  /** Configure Regular Channel
  */
  sConfig.Channel = ADC_CHANNEL_0;
  sConfig.Rank = ADC_REGULAR_RANK_2;
  if (HAL_ADC_ConfigChannel(&hadc1, &sConfig) != HAL_OK)
  {
    Error_Handler();
  }

  /** Configure Regular Channel
  */
  sConfig.Channel = ADC_CHANNEL_5;
  sConfig.Rank = ADC_REGULAR_RANK_3;
  if (HAL_ADC_ConfigChannel(&hadc1, &sConfig) != HAL_OK)
  {
    Error_Handler();
  }

  /** Configure Regular Channel
  */
  sConfig.Channel = ADC_CHANNEL_9;
  sConfig.Rank = ADC_REGULAR_RANK_4;
  if (HAL_ADC_ConfigChannel(&hadc1, &sConfig) != HAL_OK)
  {
    Error_Handler();
  }

  /** Configure Regular Channel
  */
  sConfig.Channel = ADC_CHANNEL_6;
  sConfig.Rank = ADC_REGULAR_RANK_5;
  if (HAL_ADC_ConfigChannel(&hadc1, &sConfig) != HAL_OK)
  {
    Error_Handler();
  }

  /** Configure Regular Channel
  */
  sConfig.Channel = ADC_CHANNEL_2;
  sConfig.Rank = ADC_REGULAR_RANK_6;
  if (HAL_ADC_ConfigChannel(&hadc1, &sConfig) != HAL_OK)
  {
    Error_Handler();
  }

  /** Configure Regular Channel
  */
  sConfig.Channel = ADC_CHANNEL_13;
  sConfig.Rank = ADC_REGULAR_RANK_7;
  if (HAL_ADC_ConfigChannel(&hadc1, &sConfig) != HAL_OK)
  {
    Error_Handler();
  }

  /** Configure Regular Channel
  */
  sConfig.Channel = ADC_CHANNEL_18;
  sConfig.Rank = ADC_REGULAR_RANK_8;
  if (HAL_ADC_ConfigChannel(&hadc1, &sConfig) != HAL_OK)
  {
    Error_Handler();
  }

  /** Configure Regular Channel
  */
  sConfig.Channel = ADC_CHANNEL_15;
  sConfig.Rank = ADC_REGULAR_RANK_9;
  sConfig.SamplingTime = ADC_SAMPLETIME_247CYCLES_5;
  if (HAL_ADC_ConfigChannel(&hadc1, &sConfig) != HAL_OK)
  {
    Error_Handler();
  }

}

static void MX_ADC2_Init(void)
{

  ADC_ChannelConfTypeDef sConfig = {0};

  /** Common config
  */
  hadc2.Instance = ADC2;
  hadc2.Init.ClockPrescaler = ADC_CLOCK_ASYNC_DIV64;
  hadc2.Init.Resolution = ADC_RESOLUTION_12B;
  hadc2.Init.DataAlign = ADC_DATAALIGN_RIGHT;
  hadc2.Init.ScanConvMode = ADC_SCAN_ENABLE;
  hadc2.Init.EOCSelection = ADC_EOC_SEQ_CONV;
  hadc2.Init.LowPowerAutoWait = DISABLE;
  hadc2.Init.ContinuousConvMode = ENABLE;
  hadc2.Init.NbrOfConversion = 4;
  hadc2.Init.DiscontinuousConvMode = DISABLE;
  hadc2.Init.ExternalTrigConv = ADC_SOFTWARE_START;
  hadc2.Init.ExternalTrigConvEdge = ADC_EXTERNALTRIGCONVEDGE_NONE;
  hadc2.Init.DMAContinuousRequests = ENABLE;
  hadc2.Init.SamplingMode = ADC_SAMPLING_MODE_NORMAL;
  hadc2.Init.Overrun = ADC_OVR_DATA_OVERWRITTEN;
  hadc2.Init.OversamplingMode = DISABLE;
  if (HAL_ADC_Init(&hadc2) != HAL_OK)
  {
    Error_Handler();
  }

  /** Configure Regular Channel
  */
  sConfig.Channel = ADC_CHANNEL_12;
  sConfig.Rank = ADC_REGULAR_RANK_1;
  sConfig.SamplingTime = ADC_SAMPLETIME_2CYCLES_5;
  sConfig.SingleDiff = ADC_SINGLE_ENDED;
  sConfig.OffsetNumber = ADC_OFFSET_NONE;
  sConfig.Offset = 0;
  if (HAL_ADC_ConfigChannel(&hadc2, &sConfig) != HAL_OK)
  {
    Error_Handler();
  }

  /** Configure Regular Channel
  */
  sConfig.Channel = ADC_CHANNEL_10;
  sConfig.Rank = ADC_REGULAR_RANK_2;
  if (HAL_ADC_ConfigChannel(&hadc2, &sConfig) != HAL_OK)
  {
    Error_Handler();
  }

  /** Configure Regular Channel
  */
  sConfig.Channel = ADC_CHANNEL_2;
  sConfig.Rank = ADC_REGULAR_RANK_3;
  if (HAL_ADC_ConfigChannel(&hadc2, &sConfig) != HAL_OK)
  {
    Error_Handler();
  }

  /** Configure Regular Channel
  */
  sConfig.Channel = ADC_CHANNEL_6;
  sConfig.Rank = ADC_REGULAR_RANK_4;
  if (HAL_ADC_ConfigChannel(&hadc2, &sConfig) != HAL_OK)
  {
    Error_Handler();
  }

}

static void MX_DCACHE1_Init(void)
{

  hdcache1.Instance = DCACHE1;
  hdcache1.Init.ReadBurstType = DCACHE_READ_BURST_WRAP;
  if (HAL_DCACHE_Init(&hdcache1) != HAL_OK)
  {
    Error_Handler();
  }

}

static void MX_ETH_Init(void)
{

   static uint8_t MACAddr[6];

  heth.Instance = ETH;
  MACAddr[0] = 0x00;
  MACAddr[1] = 0x80;
  MACAddr[2] = 0xE1;
  MACAddr[3] = 0x00;
  MACAddr[4] = 0x00;
  MACAddr[5] = 0x00;
  heth.Init.MACAddr = &MACAddr[0];
  heth.Init.MediaInterface = HAL_ETH_RMII_MODE;
  heth.Init.TxDesc = DMATxDscrTab;
  heth.Init.RxDesc = DMARxDscrTab;
  heth.Init.RxBuffLen = 1524;

  if (HAL_ETH_Init(&heth) != HAL_OK)
  {
    Error_Handler();
  }

}

static void MX_FDCAN2_Init(void)
{

  hfdcan2.Instance = FDCAN2;
  hfdcan2.Init.ClockDivider = FDCAN_CLOCK_DIV1;
  hfdcan2.Init.FrameFormat = FDCAN_FRAME_CLASSIC;
  hfdcan2.Init.Mode = FDCAN_MODE_NORMAL;
  hfdcan2.Init.AutoRetransmission = DISABLE;
  hfdcan2.Init.TransmitPause = DISABLE;
  hfdcan2.Init.ProtocolException = DISABLE;
  hfdcan2.Init.NominalPrescaler = 8;
  hfdcan2.Init.NominalSyncJumpWidth = 1;
  hfdcan2.Init.NominalTimeSeg1 = 11;
  hfdcan2.Init.NominalTimeSeg2 = 4;
  hfdcan2.Init.DataPrescaler = 1;
  hfdcan2.Init.DataSyncJumpWidth = 1;
  hfdcan2.Init.DataTimeSeg1 = 1;
  hfdcan2.Init.DataTimeSeg2 = 1;
  hfdcan2.Init.StdFiltersNbr = 12;
  hfdcan2.Init.ExtFiltersNbr = 8;
  hfdcan2.Init.TxFifoQueueMode = FDCAN_TX_FIFO_OPERATION;
  if (HAL_FDCAN_Init(&hfdcan2) != HAL_OK)
  {
    Error_Handler();
  }

}

static void MX_GPDMA1_Init(void)
{

  /* Peripheral clock enable */
  __HAL_RCC_GPDMA1_CLK_ENABLE();

  /* GPDMA1 interrupt Init */
    HAL_NVIC_SetPriority(GPDMA1_Channel0_IRQn, 0, 0);
    HAL_NVIC_EnableIRQ(GPDMA1_Channel0_IRQn);
    HAL_NVIC_SetPriority(GPDMA1_Channel4_IRQn, 0, 0);
    HAL_NVIC_EnableIRQ(GPDMA1_Channel4_IRQn);
    HAL_NVIC_SetPriority(GPDMA1_Channel5_IRQn, 0, 0);
    HAL_NVIC_EnableIRQ(GPDMA1_Channel5_IRQn);

}

static void MX_I2C2_Init(void)
{

  hi2c2.Instance = I2C2;
  hi2c2.Init.Timing = 0x60606293;
  hi2c2.Init.OwnAddress1 = 0;
  hi2c2.Init.AddressingMode = I2C_ADDRESSINGMODE_7BIT;
  hi2c2.Init.DualAddressMode = I2C_DUALADDRESS_DISABLE;
  hi2c2.Init.OwnAddress2 = 0;
  hi2c2.Init.OwnAddress2Masks = I2C_OA2_NOMASK;
  hi2c2.Init.GeneralCallMode = I2C_GENERALCALL_DISABLE;
  hi2c2.Init.NoStretchMode = I2C_NOSTRETCH_DISABLE;
  if (HAL_I2C_Init(&hi2c2) != HAL_OK)
  {
    Error_Handler();
  }

  /** Configure Analogue filter
  */
  if (HAL_I2CEx_ConfigAnalogFilter(&hi2c2, I2C_ANALOGFILTER_ENABLE) != HAL_OK)
  {
    Error_Handler();
  }

  /** Configure Digital filter
  */
  if (HAL_I2CEx_ConfigDigitalFilter(&hi2c2, 0) != HAL_OK)
  {
    Error_Handler();
  }

}

static void MX_ICACHE_Init(void)
{

  /** Enable instruction cache in 1-way (direct mapped cache)
  */
  if (HAL_ICACHE_ConfigAssociativityMode(ICACHE_1WAY) != HAL_OK)
  {
    Error_Handler();
  }
  if (HAL_ICACHE_Enable() != HAL_OK)
  {
    Error_Handler();
  }

}

static void MX_IWDG_Init(void)
{

  hiwdg.Instance = IWDG;
  hiwdg.Init.Prescaler = IWDG_PRESCALER_32;
  hiwdg.Init.Window = 4095;
  hiwdg.Init.Reload = 4095;
  hiwdg.Init.EWI = 0;
  if (HAL_IWDG_Init(&hiwdg) != HAL_OK)
  {
    Error_Handler();
  }

}

static void MX_LPUART1_UART_Init(void)
{

  hlpuart1.Instance = LPUART1;
  hlpuart1.Init.BaudRate = 115200;
  hlpuart1.Init.WordLength = UART_WORDLENGTH_8B;
  hlpuart1.Init.StopBits = UART_STOPBITS_1;
  hlpuart1.Init.Parity = UART_PARITY_NONE;
  hlpuart1.Init.Mode = UART_MODE_TX_RX;
  hlpuart1.Init.HwFlowCtl = UART_HWCONTROL_NONE;
  hlpuart1.Init.OneBitSampling = UART_ONE_BIT_SAMPLE_DISABLE;
  hlpuart1.AdvancedInit.AdvFeatureInit = UART_ADVFEATURE_NO_INIT;
  hlpuart1.FifoMode = UART_FIFOMODE_DISABLE;
  if (HAL_UART_Init(&hlpuart1) != HAL_OK)
  {
    Error_Handler();
  }
  if (HAL_UARTEx_SetTxFifoThreshold(&hlpuart1, UART_TXFIFO_THRESHOLD_1_8) != HAL_OK)
  {
    Error_Handler();
  }
  if (HAL_UARTEx_SetRxFifoThreshold(&hlpuart1, UART_RXFIFO_THRESHOLD_1_8) != HAL_OK)
  {
    Error_Handler();
  }
  if (HAL_UARTEx_DisableFifoMode(&hlpuart1) != HAL_OK)
  {
    Error_Handler();
  }

}

static void MX_UART7_Init(void)
{

  huart7.Instance = UART7;
  huart7.Init.BaudRate = 230400;
  huart7.Init.WordLength = UART_WORDLENGTH_8B;
  huart7.Init.StopBits = UART_STOPBITS_1;
  huart7.Init.Parity = UART_PARITY_NONE;
  huart7.Init.Mode = UART_MODE_TX;
  huart7.Init.HwFlowCtl = UART_HWCONTROL_NONE;
  huart7.Init.OverSampling = UART_OVERSAMPLING_16;
  huart7.Init.OneBitSampling = UART_ONE_BIT_SAMPLE_DISABLE;
  huart7.Init.ClockPrescaler = UART_PRESCALER_DIV1;
  huart7.AdvancedInit.AdvFeatureInit = UART_ADVFEATURE_NO_INIT;
  if (HAL_UART_Init(&huart7) != HAL_OK)
  {
    Error_Handler();
  }
  if (HAL_UARTEx_SetTxFifoThreshold(&huart7, UART_TXFIFO_THRESHOLD_1_8) != HAL_OK)
  {
    Error_Handler();
  }
  if (HAL_UARTEx_SetRxFifoThreshold(&huart7, UART_RXFIFO_THRESHOLD_1_8) != HAL_OK)
  {
    Error_Handler();
  }
  if (HAL_UARTEx_DisableFifoMode(&huart7) != HAL_OK)
  {
    Error_Handler();
  }

}

static void MX_SPI2_Init(void)
{

  /* SPI2 parameter configuration*/
  hspi2.Instance = SPI2;
  hspi2.Init.Mode = SPI_MODE_MASTER;
  hspi2.Init.Direction = SPI_DIRECTION_2LINES;
  hspi2.Init.DataSize = SPI_DATASIZE_8BIT;
  hspi2.Init.CLKPolarity = SPI_POLARITY_LOW;
  hspi2.Init.CLKPhase = SPI_PHASE_1EDGE;
  hspi2.Init.NSS = SPI_NSS_SOFT;
  hspi2.Init.BaudRatePrescaler = SPI_BAUDRATEPRESCALER_32;
  hspi2.Init.FirstBit = SPI_FIRSTBIT_MSB;
  hspi2.Init.TIMode = SPI_TIMODE_DISABLE;
  hspi2.Init.CRCCalculation = SPI_CRCCALCULATION_DISABLE;
  hspi2.Init.CRCPolynomial = 0x7;
  hspi2.Init.NSSPMode = SPI_NSS_PULSE_ENABLE;
  hspi2.Init.NSSPolarity = SPI_NSS_POLARITY_LOW;
  hspi2.Init.FifoThreshold = SPI_FIFO_THRESHOLD_01DATA;
  hspi2.Init.MasterSSIdleness = SPI_MASTER_SS_IDLENESS_00CYCLE;
  hspi2.Init.MasterInterDataIdleness = SPI_MASTER_INTERDATA_IDLENESS_00CYCLE;
  hspi2.Init.MasterReceiverAutoSusp = SPI_MASTER_RX_AUTOSUSP_DISABLE;
  hspi2.Init.MasterKeepIOState = SPI_MASTER_KEEP_IO_STATE_DISABLE;
  hspi2.Init.IOSwap = SPI_IO_SWAP_DISABLE;
  hspi2.Init.ReadyMasterManagement = SPI_RDY_MASTER_MANAGEMENT_INTERNALLY;
  hspi2.Init.ReadyPolarity = SPI_RDY_POLARITY_HIGH;
  if (HAL_SPI_Init(&hspi2) != HAL_OK)
  {
    Error_Handler();
  }

}

static void MX_GPIO_Init(void)
{
  GPIO_InitTypeDef GPIO_InitStruct = {0};

  /* GPIO Ports Clock Enable */
  __HAL_RCC_GPIOE_CLK_ENABLE();
  __HAL_RCC_GPIOC_CLK_ENABLE();
  __HAL_RCC_GPIOF_CLK_ENABLE();
  __HAL_RCC_GPIOH_CLK_ENABLE();
  __HAL_RCC_GPIOA_CLK_ENABLE();
  __HAL_RCC_GPIOB_CLK_ENABLE();
  __HAL_RCC_GPIOG_CLK_ENABLE();
  __HAL_RCC_GPIOD_CLK_ENABLE();

  /*Configure GPIO pin Output Level */
  HAL_GPIO_WritePin(GPIOE, RED_LED_Pin|GREEN_LED_Pin|PHY_RESET_Pin, GPIO_PIN_RESET);

  /*Configure GPIO pin Output Level */
  HAL_GPIO_WritePin(EF_BATTBOX_EN_GPIO_Port, EF_BATTBOX_EN_Pin, GPIO_PIN_SET);

  /*Configure GPIO pin Output Level */
  HAL_GPIO_WritePin(EF_MC_EN_GPIO_Port, EF_MC_EN_Pin, GPIO_PIN_RESET);

  /*Configure GPIO pin Output Level */
  HAL_GPIO_WritePin(GPIOD, EF_BREAK_EN_Pin|EF_FANBATT_EN_Pin|EF_PUMP1_EN_Pin|EF_PUMP2_EN_Pin
                          |EF_DASH_EN_Pin|RTDS_GPIO_Pin, GPIO_PIN_RESET);

  /*Configure GPIO pin Output Level */
  HAL_GPIO_WritePin(GPIOG, EF_RADFAN_EN_Pin|EF_SPARE_EN_Pin|WATCHDOG_Pin, GPIO_PIN_RESET);

  /*Configure GPIO pin Output Level */
  HAL_GPIO_WritePin(GPIOG, EF_SHUTDOWN_EN_Pin|FAULT_MCU_Pin, GPIO_PIN_SET);

  /*Configure GPIO pin Output Level */
  HAL_GPIO_WritePin(GPIOC, MUX_SEL1_Pin|MUX_SEL2_Pin|MUX_SEL3_Pin|MUX_SEL4_Pin, GPIO_PIN_RESET);

  /*Configure GPIO pin Output Level */
  HAL_GPIO_WritePin(EF_LV_EN_GPIO_Port, EF_LV_EN_Pin, GPIO_PIN_SET);

  /*Configure GPIO pin Output Level */
  HAL_GPIO_WritePin(IMU_CS_GPIO_Port, IMU_CS_Pin, GPIO_PIN_SET);

  /*Configure GPIO pin : USER_BUTTON_Pin */
  GPIO_InitStruct.Pin = USER_BUTTON_Pin;
  GPIO_InitStruct.Mode = GPIO_MODE_IT_FALLING;
  GPIO_InitStruct.Pull = GPIO_PULLUP;
  HAL_GPIO_Init(USER_BUTTON_GPIO_Port, &GPIO_InitStruct);

  /*Configure GPIO pins : RED_LED_Pin GREEN_LED_Pin PHY_RESET_Pin */
  GPIO_InitStruct.Pin = RED_LED_Pin|GREEN_LED_Pin|PHY_RESET_Pin;
  GPIO_InitStruct.Mode = GPIO_MODE_OUTPUT_PP;
  GPIO_InitStruct.Pull = GPIO_NOPULL;
  GPIO_InitStruct.Speed = GPIO_SPEED_FREQ_LOW;
  HAL_GPIO_Init(GPIOE, &GPIO_InitStruct);

  /*Configure GPIO pin : EF_BATTBOX_EN_Pin */
  GPIO_InitStruct.Pin = EF_BATTBOX_EN_Pin;
  GPIO_InitStruct.Mode = GPIO_MODE_OUTPUT_PP;
  GPIO_InitStruct.Pull = GPIO_PULLUP;
  GPIO_InitStruct.Speed = GPIO_SPEED_FREQ_LOW;
  HAL_GPIO_Init(EF_BATTBOX_EN_GPIO_Port, &GPIO_InitStruct);

  /*Configure GPIO pins : EF_BATTBOX_ER_Pin EF_MC_ER_Pin */
  GPIO_InitStruct.Pin = EF_BATTBOX_ER_Pin|EF_MC_ER_Pin;
  GPIO_InitStruct.Mode = GPIO_MODE_INPUT;
  GPIO_InitStruct.Pull = GPIO_PULLUP;
  HAL_GPIO_Init(GPIOF, &GPIO_InitStruct);

  /*Configure GPIO pin : EF_MC_EN_Pin */
  GPIO_InitStruct.Pin = EF_MC_EN_Pin;
  GPIO_InitStruct.Mode = GPIO_MODE_OUTPUT_PP;
  GPIO_InitStruct.Pull = GPIO_NOPULL;
  GPIO_InitStruct.Speed = GPIO_SPEED_FREQ_LOW;
  HAL_GPIO_Init(EF_MC_EN_GPIO_Port, &GPIO_InitStruct);

  /*Configure GPIO pins : BMS_GPIO_Pin BOTS_GPIO_Pin BSPD_GPIO_Pin HV_C_GPIO_Pin
                           HVD_GPIO_Pin */
  GPIO_InitStruct.Pin = BMS_GPIO_Pin|BOTS_GPIO_Pin|BSPD_GPIO_Pin|HV_C_GPIO_Pin
                          |HVD_GPIO_Pin;
  GPIO_InitStruct.Mode = GPIO_MODE_INPUT;
  GPIO_InitStruct.Pull = GPIO_NOPULL;
  HAL_GPIO_Init(GPIOF, &GPIO_InitStruct);

  /*Configure GPIO pin : FAULT_RESET_Pin */
  GPIO_InitStruct.Pin = FAULT_RESET_Pin;
  GPIO_InitStruct.Mode = GPIO_MODE_IT_FALLING;
  GPIO_InitStruct.Pull = GPIO_NOPULL;
  HAL_GPIO_Init(FAULT_RESET_GPIO_Port, &GPIO_InitStruct);

  /*Configure GPIO pin : PHY_IRQ_Pin */
  GPIO_InitStruct.Pin = PHY_IRQ_Pin;
  GPIO_InitStruct.Mode = GPIO_MODE_IT_FALLING;
  GPIO_InitStruct.Pull = GPIO_NOPULL;
  HAL_GPIO_Init(PHY_IRQ_GPIO_Port, &GPIO_InitStruct);

  /*Configure GPIO pins : PHY_GPIO_Pin IMD_GPIO_Pin */
  GPIO_InitStruct.Pin = PHY_GPIO_Pin|IMD_GPIO_Pin;
  GPIO_InitStruct.Mode = GPIO_MODE_INPUT;
  GPIO_InitStruct.Pull = GPIO_NOPULL;
  HAL_GPIO_Init(GPIOE, &GPIO_InitStruct);

  /*Configure GPIO pin : ETH_MII_RX_ER_Pin */
  GPIO_InitStruct.Pin = ETH_MII_RX_ER_Pin;
  GPIO_InitStruct.Mode = GPIO_MODE_INPUT;
  GPIO_InitStruct.Pull = GPIO_NOPULL;
  HAL_GPIO_Init(ETH_MII_RX_ER_GPIO_Port, &GPIO_InitStruct);

  /*Configure GPIO pins : EF_BREAK_EN_Pin EF_FANBATT_EN_Pin EF_PUMP1_EN_Pin EF_PUMP2_EN_Pin
                           EF_DASH_EN_Pin RTDS_GPIO_Pin */
  GPIO_InitStruct.Pin = EF_BREAK_EN_Pin|EF_FANBATT_EN_Pin|EF_PUMP1_EN_Pin|EF_PUMP2_EN_Pin
                          |EF_DASH_EN_Pin|RTDS_GPIO_Pin;
  GPIO_InitStruct.Mode = GPIO_MODE_OUTPUT_PP;
  GPIO_InitStruct.Pull = GPIO_NOPULL;
  GPIO_InitStruct.Speed = GPIO_SPEED_FREQ_LOW;
  HAL_GPIO_Init(GPIOD, &GPIO_InitStruct);

  /*Configure GPIO pins : EF_BREAK_ER_Pin EF_FANBATT_ER_Pin EF_PUMP1_ER_Pin EF_PUMP2_ER_Pin
                           EF_DASH_ER_Pin EF_LV_ER_Pin */
  GPIO_InitStruct.Pin = EF_BREAK_ER_Pin|EF_FANBATT_ER_Pin|EF_PUMP1_ER_Pin|EF_PUMP2_ER_Pin
                          |EF_DASH_ER_Pin|EF_LV_ER_Pin;
  GPIO_InitStruct.Mode = GPIO_MODE_INPUT;
  GPIO_InitStruct.Pull = GPIO_PULLUP;
  HAL_GPIO_Init(GPIOD, &GPIO_InitStruct);

  /*Configure GPIO pins : CKPT_GPIO_Pin INERTIA_SW_GPIO_Pin TSMS_GPIO_Pin */
  GPIO_InitStruct.Pin = CKPT_GPIO_Pin|INERTIA_SW_GPIO_Pin|TSMS_GPIO_Pin;
  GPIO_InitStruct.Mode = GPIO_MODE_INPUT;
  GPIO_InitStruct.Pull = GPIO_NOPULL;
  HAL_GPIO_Init(GPIOG, &GPIO_InitStruct);

  /*Configure GPIO pins : EF_RADFAN_EN_Pin EF_SPARE_EN_Pin WATCHDOG_Pin FAULT_MCU_Pin */
  GPIO_InitStruct.Pin = EF_RADFAN_EN_Pin|EF_SPARE_EN_Pin|WATCHDOG_Pin|FAULT_MCU_Pin;
  GPIO_InitStruct.Mode = GPIO_MODE_OUTPUT_PP;
  GPIO_InitStruct.Pull = GPIO_NOPULL;
  GPIO_InitStruct.Speed = GPIO_SPEED_FREQ_LOW;
  HAL_GPIO_Init(GPIOG, &GPIO_InitStruct);

  /*Configure GPIO pins : EF_RADFAN_ER_Pin EF_SHUTDOWN_ER_Pin EF_SPARE_ER_Pin */
  GPIO_InitStruct.Pin = EF_RADFAN_ER_Pin|EF_SHUTDOWN_ER_Pin|EF_SPARE_ER_Pin;
  GPIO_InitStruct.Mode = GPIO_MODE_INPUT;
  GPIO_InitStruct.Pull = GPIO_PULLUP;
  HAL_GPIO_Init(GPIOG, &GPIO_InitStruct);

  /*Configure GPIO pin : EF_SHUTDOWN_EN_Pin */
  GPIO_InitStruct.Pin = EF_SHUTDOWN_EN_Pin;
  GPIO_InitStruct.Mode = GPIO_MODE_OUTPUT_PP;
  GPIO_InitStruct.Pull = GPIO_PULLUP;
  GPIO_InitStruct.Speed = GPIO_SPEED_FREQ_LOW;
  HAL_GPIO_Init(EF_SHUTDOWN_EN_GPIO_Port, &GPIO_InitStruct);

  /*Configure GPIO pins : MUX_SEL1_Pin MUX_SEL2_Pin MUX_SEL3_Pin MUX_SEL4_Pin */
  GPIO_InitStruct.Pin = MUX_SEL1_Pin|MUX_SEL2_Pin|MUX_SEL3_Pin|MUX_SEL4_Pin;
  GPIO_InitStruct.Mode = GPIO_MODE_OUTPUT_PP;
  GPIO_InitStruct.Pull = GPIO_NOPULL;
  GPIO_InitStruct.Speed = GPIO_SPEED_FREQ_LOW;
  HAL_GPIO_Init(GPIOC, &GPIO_InitStruct);

  /*Configure GPIO pin : IMU_INT2_Pin */
  GPIO_InitStruct.Pin = IMU_INT2_Pin;
  GPIO_InitStruct.Mode = GPIO_MODE_IT_RISING;
  GPIO_InitStruct.Pull = GPIO_NOPULL;
  HAL_GPIO_Init(IMU_INT2_GPIO_Port, &GPIO_InitStruct);

  /*Configure GPIO pin : EF_LV_EN_Pin */
  GPIO_InitStruct.Pin = EF_LV_EN_Pin;
  GPIO_InitStruct.Mode = GPIO_MODE_OUTPUT_PP;
  GPIO_InitStruct.Pull = GPIO_PULLUP;
  GPIO_InitStruct.Speed = GPIO_SPEED_FREQ_LOW;
  HAL_GPIO_Init(EF_LV_EN_GPIO_Port, &GPIO_InitStruct);

  /*Configure GPIO pin : IMU_CS_Pin */
  GPIO_InitStruct.Pin = IMU_CS_Pin;
  GPIO_InitStruct.Mode = GPIO_MODE_OUTPUT_PP;
  GPIO_InitStruct.Pull = GPIO_NOPULL;
  GPIO_InitStruct.Speed = GPIO_SPEED_FREQ_LOW;
  HAL_GPIO_Init(IMU_CS_GPIO_Port, &GPIO_InitStruct);

  /* EXTI interrupt init*/
  HAL_NVIC_SetPriority(EXTI2_IRQn, 0, 0);
  HAL_NVIC_EnableIRQ(EXTI2_IRQn);

  HAL_NVIC_SetPriority(EXTI8_IRQn, 0, 0);
  HAL_NVIC_EnableIRQ(EXTI8_IRQn);

  HAL_NVIC_SetPriority(EXTI11_IRQn, 0, 0);
  HAL_NVIC_EnableIRQ(EXTI11_IRQn);

}

/* USER CODE BEGIN 4 */

/* Interrupt handler. */
void HAL_GPIO_EXTI_Callback(uint16_t GPIO_Pin)
{
  switch(GPIO_Pin) {
    case USER_BUTTON_Pin: debug_onUserButtonPressed(); break;
  }
}

/* USER CODE END 4 */

void HAL_TIM_PeriodElapsedCallback(TIM_HandleTypeDef *htim)
{
  if (htim->Instance == TIM1)
  {
    HAL_IncTick();
  }
}

void Error_Handler(void)
{
  __disable_irq();
  while (1)
  {
  }
}
